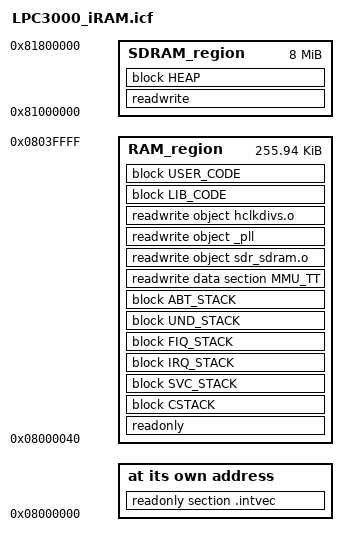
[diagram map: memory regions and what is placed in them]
/*###ICF### Section handled by ICF editor, don't touch! ****/
/*-Editor annotation file-*/
/* IcfEditorFile="$TOOLKIT_DIR$\config\ide\IcfEditor\a_v1_0.xml" */
/*-Specials-*/
define symbol __ICFEDIT_intvec_start__ = 0x08000000;
/*-Memory Regions-*/
define symbol __ICFEDIT_region_ROM_start__   = 0x00;
define symbol __ICFEDIT_region_ROM_end__     = 0x00;
define symbol __ICFEDIT_region_RAM_start__   = 0x08000040;
define symbol __ICFEDIT_region_RAM_end__     = 0x0803FFFF;
define symbol __ICFEDIT_region_SDRAM_start__   = 0x81000000;
define symbol __ICFEDIT_region_SDRAM_end__     = 0x81800000;

/*-Sizes-*/
define symbol __ICFEDIT_size_cstack__   = 0x1F40;
define symbol __ICFEDIT_size_svcstack__ = 0x40;
define symbol __ICFEDIT_size_irqstack__ = 0x500;
define symbol __ICFEDIT_size_fiqstack__ = 0x0;
define symbol __ICFEDIT_size_undstack__ = 0x0;
define symbol __ICFEDIT_size_abtstack__ = 0x0;
define symbol __ICFEDIT_size_heap__     = 0x040000;
/**** End of ICF editor section. ###ICF###*/

define memory mem with size = 4G;
define region RAM_region   = mem:[from __ICFEDIT_region_RAM_start__   to __ICFEDIT_region_RAM_end__];
define region SDRAM_region   = mem:[from __ICFEDIT_region_SDRAM_start__   to __ICFEDIT_region_SDRAM_end__];

define block CSTACK    with alignment = 8, size = __ICFEDIT_size_cstack__   { };
define block SVC_STACK with alignment = 8, size = __ICFEDIT_size_svcstack__ { };
define block IRQ_STACK with alignment = 8, size = __ICFEDIT_size_irqstack__ { };
define block FIQ_STACK with alignment = 8, size = __ICFEDIT_size_fiqstack__ { };
define block UND_STACK with alignment = 8, size = __ICFEDIT_size_undstack__ { };
define block ABT_STACK with alignment = 8, size = __ICFEDIT_size_abtstack__ { };
define block HEAP      with alignment = 8, size = __ICFEDIT_size_heap__     { };

define block LIB_CODE with fixed order
{
readwrite object board_nand_ids.o,
readwrite object lpc32xx_adc_driver.o,
readwrite object lpc32xx_clcdc_driver.o,
readwrite object lpc32xx_clkpwr_driver.o,
readwrite object lpc32xx_dma_driver.o,
readwrite object lpc32xx_gpio_driver.o,
readwrite object lpc32xx_hstimer_driver.o,
readwrite object lpc32xx_hsuart_driver.o,
readwrite object lpc32xx_i2c_driver.o,
readwrite object lpc32xx_i2s_driver.o,
readwrite object lpc32xx_intc_driver.o,
readwrite object lpc32xx_kscan_driver.o,
readwrite object lpc32xx_mlcnand_driver.o,
readwrite object lpc32xx_mstimer_driver.o,
readwrite object lpc32xx_mstr_i2c_driver.o,
readwrite object lpc32xx_pwm_driver.o,
readwrite object lpc32xx_rtc_driver.o,
readwrite object lpc32xx_sdcard_driver.o,
readwrite object lpc32xx_slcnand_driver.o,
readwrite object lpc32xx_spi_driver.o,
readwrite object lpc32xx_ssp_driver.o,
readwrite object lpc32xx_timer_driver.o,
readwrite object lpc32xx_tsc_driver.o,
readwrite object lpc32xx_uart_driver.o,
readwrite object lpc32xx_wdt_driver.o,
readwrite object lpc3xxx_spwm_driver.o,
readwrite object phy3250_board.o
};

define block USER_CODE with fixed order
{
readwrite object _aic23.o,
readwrite object _boost_tpa6011.o,
readwrite object _crypt.o,
readwrite object _i2c.o,
readwrite object _i2s.o,
readwrite object _nand_slc.o,
readwrite object _pll.o,
readwrite object _sdcard.o,
readwrite object _sdcard_spi.o,
readwrite object _wd.o,
readwrite object charger.o,
readwrite object drv_booster.o,
readwrite object keeper.o,
readwrite object keyb.o,
readwrite object max98_example.o,
readwrite object max98089_dr.o,
readwrite object max98089_driver.o,
readwrite object sdr_sdram.o,
readwrite object sdram_common.o,
readwrite object write.o
};

initialize by copy with packing = zeros { readwrite }
	except { section .intvec, readwrite object sdram_common.o, readwrite object sdr_sdram.o, 
			readwrite object _pll, readwrite object hclkdivs.o};
 

/*initialize by copy { readonly, readwrite };*/
do not initialize  { section .noinit };
do not initialize  { section MMU_TT };

place at address mem:__ICFEDIT_intvec_start__ { readonly section .intvec };

place in RAM_region   { readonly };
/*place in RAM_region   { readwrite,
                        block CSTACK, block SVC_STACK, block IRQ_STACK, block FIQ_STACK,
                        block UND_STACK, block ABT_STACK, 
                        readwrite data section MMU_TT };*/

place in RAM_region   { block CSTACK, block SVC_STACK, block IRQ_STACK, block FIQ_STACK,
                        block UND_STACK, block ABT_STACK, 
                        readwrite data section MMU_TT, readwrite object sdr_sdram.o, 
						readwrite object _pll, readwrite object hclkdivs.o, block LIB_CODE, block USER_CODE};

place in SDRAM_region   { readwrite, block HEAP};

/*place in SDRAM_region {block HEAP};*/
